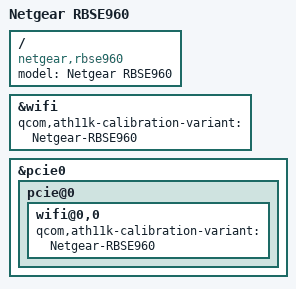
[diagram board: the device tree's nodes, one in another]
// SPDX-License-Identifier: GPL-2.0-or-later OR MIT

/dts-v1/;

#include "ipq8074-rbxe960.dtsi"

/ {
	model = "Netgear RBSE960";
	compatible = "netgear,rbse960", "qcom,ipq8074";
};

&wifi {
	qcom,ath11k-calibration-variant = "Netgear-RBSE960";
};

&pcie0 {
	pcie@0 {
		wifi@0,0 {
			qcom,ath11k-calibration-variant = "Netgear-RBSE960";
		};
	};
};
